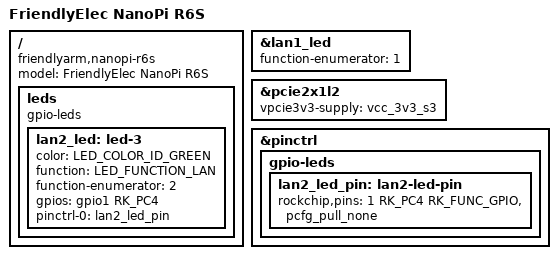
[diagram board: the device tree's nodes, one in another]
// SPDX-License-Identifier: (GPL-2.0+ OR MIT)

/dts-v1/;

#include "rk3588s-nanopi-r6.dtsi"

/ {
	model = "FriendlyElec NanoPi R6S";
	compatible = "friendlyarm,nanopi-r6s", "rockchip,rk3588s";

	leds {
		compatible = "gpio-leds";

		lan2_led: led-3 {
			color = <LED_COLOR_ID_GREEN>;
			function = LED_FUNCTION_LAN;
			function-enumerator = <2>;
			gpios = <&gpio1 RK_PC4 GPIO_ACTIVE_HIGH>;
			pinctrl-names = "default";
			pinctrl-0 = <&lan2_led_pin>;
		};
	};
};

&lan1_led {
	function-enumerator = <1>;
};

/* RTL8125BG Ethernet */
&pcie2x1l2 {
	vpcie3v3-supply = <&vcc_3v3_s3>;
};

&pinctrl {
	gpio-leds {
		lan2_led_pin: lan2-led-pin {
			rockchip,pins = <1 RK_PC4 RK_FUNC_GPIO &pcfg_pull_none>;
		};
	};
};
